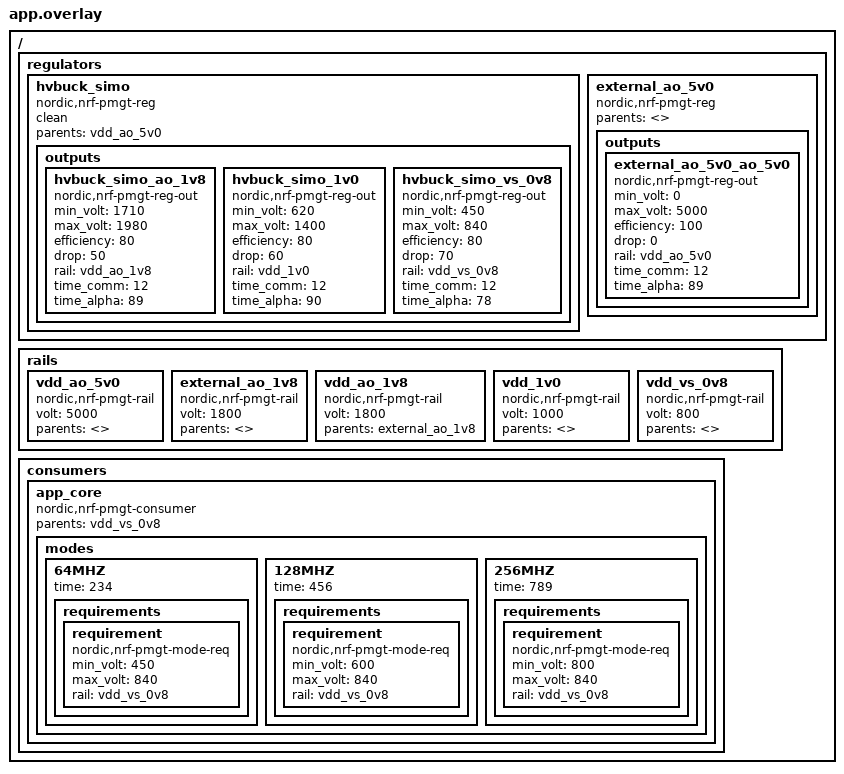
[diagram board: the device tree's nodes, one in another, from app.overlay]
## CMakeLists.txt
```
#
# Copyright (c) 2020 Nordic Semiconductor
#
# SPDX-License-Identifier: LicenseRef-BSD-5-Clause-Nordic
#

cmake_minimum_required(VERSION 3.8.2)

include($ENV{ZEPHYR_BASE}/cmake/app/boilerplate.cmake NO_POLICY_SCOPE)
project("SYSCTRL application")

# Include application event headers
zephyr_library_include_directories(src/events)
zephyr_library_include_directories(src/modules/messaging)
zephyr_library_include_directories(src/modules/tmr_mngr)
zephyr_library_include_directories(src/modules/power_management)

# Application sources
# NORDIC SDK APP START
target_sources(app PRIVATE src/main.c)

target_sources(app PRIVATE
		src/events/clock_event.c
		src/events/status_event.c
		src/events/led_event.c
		src/events/gpms_event.c
		src/events/prism_event.c
		src/events/ld_notify_event.c
		src/events/radio_event.c
		src/events/mts_event.c
		src/events/temp_event.c
)

target_sources(app PRIVATE
		src/modules/dummy/leds.c
		src/modules/power_management/gpms.c
		src/modules/power_management/power_control.c
		src/modules/power_management/clock_control.c
		src/modules/power_management/nrf_gpms.c
		src/modules/messaging/filter.c
		src/modules/messaging/prism_dispatcher.c
		src/modules/messaging/ncm.c
		src/modules/tmr_mngr/pot.c
		src/modules/tmr_mngr/tmr_mngr.c
		src/modules/tmr_mngr/tmr_mngr_backend.c
		src/modules/memory_transfer/mts.c
		src/modules/temperature/temp.c
)

# NORDIC SDK APP END
```

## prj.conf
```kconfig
#
# Copyright (c) 2019 Nordic Semiconductor ASA
#
# SPDX-License-Identifier: LicenseRef-BSD-5-Clause-Nordic
#
# Enabling assert
CONFIG_ASSERT=y

# Logger configuration
CONFIG_LOG=y
CONFIG_LOG_DEFAULT_LEVEL=2
CONFIG_LOG_BACKEND_UART=y
CONFIG_LOG_STRDUP_BUF_COUNT=10

# Configuration required by Event Manager
CONFIG_EVENT_MANAGER=y
CONFIG_LINKER_ORPHAN_SECTION_PLACE=y
CONFIG_HEAP_MEM_POOL_SIZE=2048
CONFIG_REBOOT=y

# Configuration required by Prism Dispatcher
CONFIG_IPM=y
CONFIG_IPM_NRFX=y
CONFIG_IPM_MSG_CH_0_ENABLE=y
CONFIG_IPM_MSG_CH_1_ENABLE=y
CONFIG_IPM_MSG_CH_0_TX=y
CONFIG_IPM_MSG_CH_1_RX=y

CONFIG_PRISM_DISPATCHER=y
CONFIG_PRISM_DISPATCHER_ALGO_SINGLEBUF=y
CONFIG_PRISM_DISPATCHER_BACKEND_OPENAMP=y
CONFIG_PRISM_DISPATCHER_APP_ENABLED=y
CONFIG_PRISM_DISPATCHER_EPT_COUNT=1
CONFIG_PRISM_DISPATCHER_MSG_SIZE=128

CONFIG_RPMSG_MASTER=y

CONFIG_TEST_RANDOM_GENERATOR=y

CONFIG_PM_ENABLE=y

CONFIG_NRFS=y
```

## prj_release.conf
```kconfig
#
# Copyright (c) 2019 Nordic Semiconductor ASA
#
# SPDX-License-Identifier: LicenseRef-BSD-5-Clause-Nordic
#
# Disable assert
CONFIG_ASSERT=n

# Disable logging
CONFIG_LOG=n
CONFIG_CONSOLE=n
CONFIG_SERIAL=n
CONFIG_UART_CONSOLE=n
CONFIG_STDOUT_CONSOLE=n
CONFIG_PRINTK=n

# Disable MPU & TRUSTZONE
CONFIG_ARM_MPU=n
CONFIG_ARM_TRUSTZONE_M=n

# Disable redundant kernel functionalities
CONFIG_THREAD_STACK_INFO=n
CONFIG_ERRNO=n

# Keep system stacks sizes minimal
CONFIG_ISR_STACK_SIZE=64
CONFIG_MAIN_STACK_SIZE=128
CONFIG_IDLE_STACK_SIZE=32
CONFIG_SYSTEM_WORKQUEUE_STACK_SIZE=512

# Configuration required by Event Manager
CONFIG_EVENT_MANAGER=y
CONFIG_LINKER_ORPHAN_SECTION_PLACE=y
CONFIG_HEAP_MEM_POOL_SIZE=512
CONFIG_REBOOT=y

# Configuration required by Prism Dispatcher
CONFIG_IPM=y
CONFIG_IPM_NRFX=y
CONFIG_IPM_MSG_CH_0_ENABLE=y
CONFIG_IPM_MSG_CH_1_ENABLE=y
CONFIG_IPM_MSG_CH_0_TX=y
CONFIG_IPM_MSG_CH_1_RX=y

CONFIG_PRISM_DISPATCHER=y
CONFIG_PRISM_DISPATCHER_ALGO_SINGLEBUF=y
CONFIG_PRISM_DISPATCHER_BACKEND_OPENAMP=y
CONFIG_PRISM_DISPATCHER_APP_ENABLED=y
CONFIG_PRISM_DISPATCHER_EPT_COUNT=1
CONFIG_PRISM_DISPATCHER_MSG_SIZE=128

CONFIG_RPMSG_MASTER=y

CONFIG_TEST_RANDOM_GENERATOR=y

CONFIG_PM_ENABLE=y

CONFIG_NRFS=y
```

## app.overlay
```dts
/ {
	regulators {

		hvbuck_simo {

			compatible = "nordic,nrf-pmgt-reg";

			clean;
			parents   = <&vdd_ao_5v0>;

			outputs {

				hvbuck_simo_ao_1v8 {
					compatible = "nordic,nrf-pmgt-reg-out";
					min_volt   = <1710>;
					max_volt   = <1980>;
					efficiency = <80>;
					drop	   = <50>;
					rail	   = <&vdd_ao_1v8>;
					time_comm  = <12>;
					time_alpha = <89>;
					/* time to change voltage = time_comm + (deltaV * time_alpha) */
				};

				hvbuck_simo_1v0 {
					compatible = "nordic,nrf-pmgt-reg-out";
					min_volt   = <620>;
					max_volt   = <1400>;
					efficiency = <80>;
					drop	   = <60>;
					rail	   = <&vdd_1v0>;
					time_comm  = <12>;
					time_alpha = <90>;
				};

				hvbuck_simo_vs_0v8 {
					compatible = "nordic,nrf-pmgt-reg-out";
					min_volt   = <450>;
					max_volt   = <840>;
					efficiency = <80>;
					drop	   = <70>;
					rail	   = <&vdd_vs_0v8>;
					time_comm  = <12>;
					time_alpha = <78>;
				};

			};


		};

		external_ao_5v0 {
			compatible = "nordic,nrf-pmgt-reg";
			parents	= <>;

			outputs {
				external_ao_5v0_ao_5v0 {
					compatible = "nordic,nrf-pmgt-reg-out";
					min_volt   = <0>;
					max_volt   = <5000>;
					efficiency = <100>;
					drop	   = <0>;
					rail	   = <&vdd_ao_5v0>;
					time_comm  = <12>;
					time_alpha = <89>;
					/* time to change voltage = time_comm + (deltaV * time_alpha) */
				};
			};
		};

		/* ... other regulators ... */

	};

	rails {
		vdd_ao_5v0: vdd_ao_5v0 {
			compatible = "nordic,nrf-pmgt-rail";
			volt = <5000>;
			parents = <>;
		};

		external_ao_1v8: external_ao_1v8 {
			compatible = "nordic,nrf-pmgt-rail";
			volt = <1800>;
			parents = <>;
		};

		vdd_ao_1v8: vdd_ao_1v8 {
			compatible = "nordic,nrf-pmgt-rail";
			volt = <1800>;
			parents = <&external_ao_1v8>;
		};

		vdd_1v0: vdd_1v0 {
			compatible = "nordic,nrf-pmgt-rail";
			volt = <1000>;
			parents = <>;
		};

		vdd_vs_0v8: vdd_vs_0v8 {
			compatible = "nordic,nrf-pmgt-rail";
			volt = <800>;
			parents = <>;
		};

		/* ... other rails ... */
	};


	consumers {

		app_core {
			compatible = "nordic,nrf-pmgt-consumer";
			parents    = <&vdd_vs_0v8>;

			modes {

				/* OFF is implied */

				64MHZ {
					time	 = <234>;
					requirements {
						requirement {
							compatible = "nordic,nrf-pmgt-mode-req";
							min_volt  = <450>;
							max_volt  = <840>;
							rail	  = <&vdd_vs_0v8>;
						};
					};

				};

				128MHZ {
					time	 = <456>;
					requirements {
						requirement {
							compatible = "nordic,nrf-pmgt-mode-req";
							min_volt  = <600>;
							max_volt  = <840>;
							rail	  = <&vdd_vs_0v8>;
						};
					};

				};

				256MHZ {
					time	 = <789>;
					requirements {
						requirement {
							compatible = "nordic,nrf-pmgt-mode-req";
							min_volt  = <800>;
							max_volt  = <840>;
							rail	  = <&vdd_vs_0v8>;
						};
					};

				};

			};

		};

		/* ... other cores ... */

	};

};
```

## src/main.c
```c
/*
 * Copyright (c) 2020 Nordic Semiconductor ASA
 *
 * SPDX-License-Identifier: LicenseRef-BSD-5-Clause-Nordic
 */

#include <event_manager.h>
#include <status_event.h>

#include <logging/log.h>
LOG_MODULE_REGISTER(MAIN, 4);

void main(void)
{
	LOG_ERR("Start");
	if (event_manager_init()) {
		LOG_ERR("Event Manager not initialized");
	} else {
		struct status_event *event = new_status_event();
		event->status = STATUS_INIT;
		EVENT_SUBMIT(event);
	}
}
```
